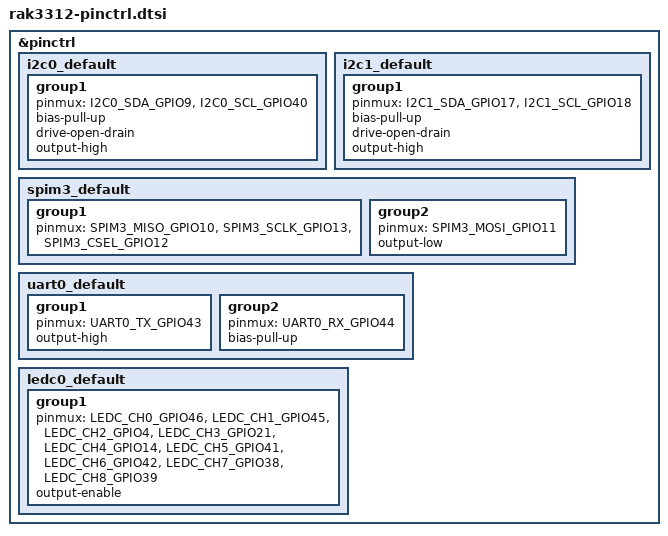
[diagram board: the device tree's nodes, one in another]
/*
 * SPDX-License-Identifier: Apache-2.0
 * Copyright (c) 2026 Shenzhen RAKwireless Technology Co., Ltd.
 */

&pinctrl {
	i2c0_default: i2c0_default {
		group1 {
			pinmux = <I2C0_SDA_GPIO9>, <I2C0_SCL_GPIO40>;
			bias-pull-up;
			drive-open-drain;
			output-high;
		};
	};

	i2c1_default: i2c1_default {
		group1 {
			pinmux = <I2C1_SDA_GPIO17>, <I2C1_SCL_GPIO18>;
			bias-pull-up;
			drive-open-drain;
			output-high;
		};
	};

	spim3_default: spim3_default {
		group1 {
			pinmux = <SPIM3_MISO_GPIO10>,
				 <SPIM3_SCLK_GPIO13>,
				 <SPIM3_CSEL_GPIO12>;
		};

		group2 {
			pinmux = <SPIM3_MOSI_GPIO11>;
			output-low;
		};
	};

	uart0_default: uart0_default {
		group1 {
			pinmux = <UART0_TX_GPIO43>;
			output-high;
		};

		group2 {
			pinmux = <UART0_RX_GPIO44>;
			bias-pull-up;
		};
	};

	ledc0_default: ledc0_default {
		group1 {
			pinmux = <LEDC_CH0_GPIO46>,
				 <LEDC_CH1_GPIO45>,
				 <LEDC_CH2_GPIO4>,
				 <LEDC_CH3_GPIO21>,
				 <LEDC_CH4_GPIO14>,
				 <LEDC_CH5_GPIO41>,
				 <LEDC_CH6_GPIO42>,
				 <LEDC_CH7_GPIO38>,
				 <LEDC_CH8_GPIO39>;
			output-enable;
		};
	};

};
